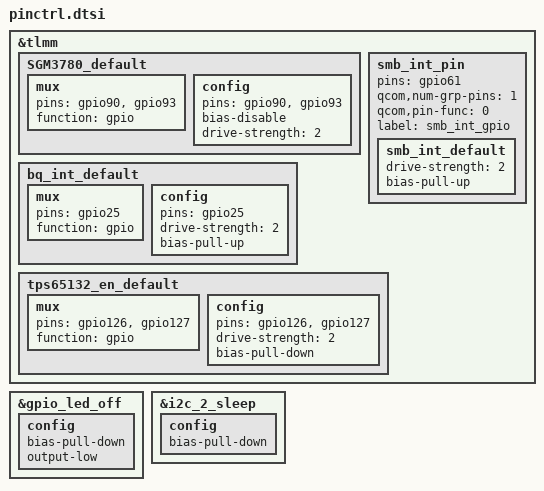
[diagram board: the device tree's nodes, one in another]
/* From stock msm8917-camera-pinctrl.dtsi */
&tlmm {
	SGM3780_default: SGM3780_default {
		mux {
			pins = "gpio90", "gpio93";
			function = "gpio";
		};

		config {
			pins = "gpio90", "gpio93";
			bias-disable; /* No PULL */
			drive-strength = <2>; /* 2 MA */
		};
	};
};

/* From stock msm8917-pinctrl.dtsi */
&tlmm {
	smb_int_pin {
		pins = "gpio61";
		qcom,num-grp-pins = <1>;
		qcom,pin-func = <0>;
		label = "smb_int_gpio";
		smb_int_default: smb_int_default {
			drive-strength = <2>;	/*8 MA */
			bias-pull-up;		/* PULL UP*/
		};
	};
	bq_int_default: bq_int_default {
		mux {
			pins = "gpio25";
			function ="gpio";
		};
		config {
			pins = "gpio25";
			drive-strength = <2>; /* 2 MA */
			bias-pull-up;
			/* PULL UP*/
			};
	};
	tps65132_en_default: tps65132_en_default {
		mux {
			pins = "gpio126", "gpio127";
			function = "gpio";
		};
		config {
			pins = "gpio126", "gpio127";
			drive-strength = <2>;
			bias-pull-down;
		};
	};
};
&gpio_led_off {
	config {
		bias-pull-down;
		output-low;
	};
};
&i2c_2_sleep {
	config {
		/delete-property/ bias-disable;
		bias-pull-down;
	};
};
